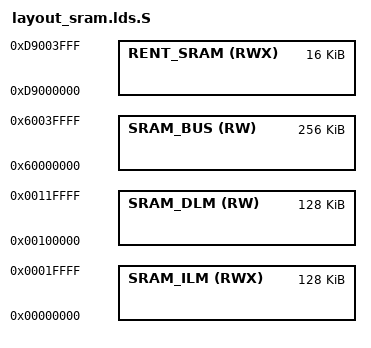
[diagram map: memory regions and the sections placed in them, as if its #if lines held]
MEMORY
{
#if (SETTING_SRAM_OPTION == 1)
    SRAM_ILM    (RWX)     : ORIGIN = 0x00000000, LENGTH = 128K
    SRAM_DLM    (RW)      : ORIGIN = 0x00100000, LENGTH = 128K
#endif
    SRAM_BUS    (RW)      : ORIGIN = 0x60000000, LENGTH = 256K
    RENT_SRAM   (RWX)     : ORIGIN = 0xD9000000, LENGTH = 16K

    /* ota_data(4K), sa_table(4K), mac_table(4K), pad_table(4K), ROM_BOOT(4K)*/
}

#if (SETTING_SRAM_OPTION == 1)
REGION_ALIAS("REGION_TEXT_FAST" , SRAM_ILM);
#else
REGION_ALIAS("REGION_TEXT_FAST" , SRAM_BUS);
#endif
REGION_ALIAS("REGION_BOOT"      , SRAM_BUS);
REGION_ALIAS("REGION_BURN"      , SRAM_BUS);
REGION_ALIAS("REGION_MAIN1"     , SRAM_BUS);
#if (SETTING_SRAM_OPTION == 1)
REGION_ALIAS("REGION_DATA"      , SRAM_DLM);
REGION_ALIAS("REGION_DATA_FAST" , SRAM_DLM);
REGION_ALIAS("REGION_BSS"       , SRAM_DLM);
#else
REGION_ALIAS("REGION_DATA"      , SRAM_BUS);
REGION_ALIAS("REGION_DATA_FAST" , SRAM_BUS);
REGION_ALIAS("REGION_BSS"       , SRAM_BUS);
#endif
REGION_ALIAS("REGION_LPRAM"     , RENT_SRAM);
